# STM32MP25_CM33 register map
File version: 1.3
CPU: CM33 r0p1, little endian, MPU, FPU, vendor SysTick, 8 interrupt priority bits
Registers are 32-bit, read-write, reset 0x0 unless marked. A register's access mark holds for its fields unless they carry their own. Offsets are from the block's base; [hi:lo] are bit positions; lines under a group give offsets from that group; {n}, {i} and the like mark numbered series; 'fields as' and 'values as' point back to an identical list.

## ETHSW (part 1 of 2) — ETHSW register block
Base 0x4C000000
Same registers: ETHSW_S 0x5C000000
0x00 ETHSW_AC_DEV_IDR ro reset 0xD000 — ETHSW AC device ID register
  [23:8] DEVICE_ID
    208=AC
0x04 ETHSW_AC_INT_IDR ro reset 0x17E4078 — ETHSW AC int ID register
  [31:0] INT_ID — IP core version
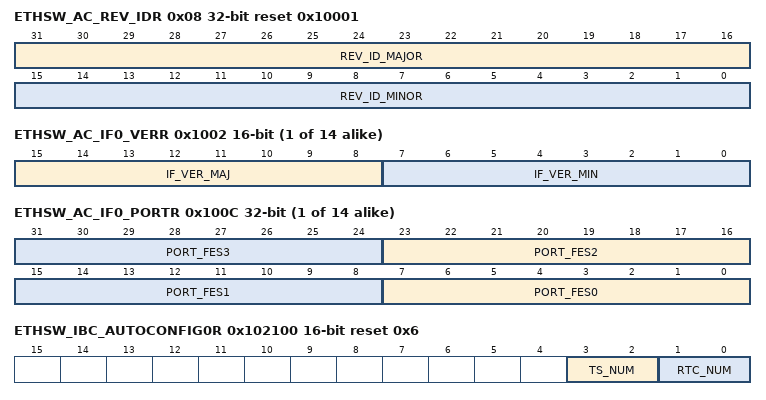
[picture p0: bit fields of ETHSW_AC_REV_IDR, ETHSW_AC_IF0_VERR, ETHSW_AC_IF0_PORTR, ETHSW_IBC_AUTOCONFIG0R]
0x08 ETHSW_AC_REV_IDR ro reset 0x10001 — ETHSW AC revision ID register
  [31:16] REV_ID_MAJOR — Revision ID major number
  [15:0] REV_ID_MINOR — Revision ID minor number
{0x1000+0x10*i} ETHSW_AC_IF{i}_IDR 16-bit ro (i=0..13) — ETHSW AC interface {i} ID register
  [15:0] INTERFACE_ID — Interface identification
    0=End of table; 1=Interface Map (this map); 16=Switch Management (of FES); 17=Switch Parameters (of FES); 18=Port Control Array (of FES); 19=Port Status Array (of FES); 20=Preemption (of FES); 21=Shapers (of FES); 22=Cut-Through (of FES); 23=HSR/PRP (of FES); 24=MACsec (of FES); 25=Port Timestamper (of FES); 26=Stream Identification (of FES); 27=Frame Replication and Elimination for Reliability (of FES); 28=Per-Stream Filtering and Policing (of FES); 32=Scheduled Traffic; 48=Clock; 64=Ethernet Interface Adapters
{0x1002+0x10*i} ETHSW_AC_IF{i}_VERR 16-bit ro (i=0..13) — ETHSW AC interface {i} version register
  [15:8] IF_VER_MAJ — Interface major number
  [7:0] IF_VER_MIN — Interface minor number
{0x1004+0x10*i} ETHSW_AC_IF{i}_BASER ro (i=0..13) — ETHSW AC interface {i} base address register
  [31:0] BASE — Base address
{0x1008+0x10*i} ETHSW_AC_IF{i}_LENR ro (i=0..13) — ETHSW AC interface {i} length register
  [31:0] LEN — Interface length
{0x100C+0x10*i} ETHSW_AC_IF{i}_PORTR ro (i=0..13) — ETHSW AC interface {i} port mapping register
  [all] fields
    0=not mapped to corresponding port of FES; 1=mapped to corresponding port of FES
  [8n+7:8n] PORT_FES{n} (n=0..3) — Port mapping to FES_{n}
0x10E0 ETHSW_AC_EOTR 16-bit ro — ETHSW AC end of table register
  [15:0] END_OF_TABLE — Static value 0x0 indicating end of table.
0x100000 ETHSW_IBC_DEV_IDR ro reset 0xE000 — ETHSW IBC device ID register
  [23:8] DEVICE_ID
    224=IBC
0x100004 ETHSW_IBC_INT_IDR ro reset 0x16A9932 — ETHSW IBC IP core ID register
  [31:0] INT_ID — IP core version
0x101000 ETHSW_IBC_GP_MUX_CTRLR 16-bit — ETHSW IBC general-purpose multiplexer control register
  [0] GPMUX0 — General-purpose (GP) multiplexer 0 control
    0=gp_in_a(0) connected to gp_out(0); 1=gp_in_b(0) connected to gp_out(0)
0x101100 ETHSW_IBC_TIME_MUX_CTRLR 16-bit — ETHSW IBC time interface mux demux control register
  [0] TIM_MUX0 — Time interface (TI) mux/demux 0 control
    0=time_in_a(0) connected to time_out(0), time_req_in(0) connected to time_req_out_a(0); 1=time_in_b(0) connected to time_out(0), time_req_in(0) connected to time_req_out_b(0)
0x102000 ETHSW_IBC_GP_MUXESR 16-bit ro reset 0x1 — ETHSW IBC generic GP_MUXES register
  [1:0] GPMUXES — The value of generic GP_MUXES
0x102002 ETHSW_IBC_GP_MUX_DEFAULTR 16-bit ro — ETHSW IBC generic GP_MUX_DEFAULT register
  [1:0] GPMUXDEF — The value of Generic GP_MUX_DEFAULT
0x102004 ETHSW_IBC_TIME_MUXESR 16-bit ro reset 0x1 — ETHSW IBC generic TIME_MUXES register
  [1:0] TIME_MUX — The value of Generic TIME_MUXES
0x102006 ETHSW_IBC_TIME_MUX_DEFAULTR 16-bit ro — ETHSW IBC generic TIME_MUX_DEFAULT register
  [1:0] TIM_MUXDEF — The value of Generic TIME_MUX_DEFAULT
0x102100 ETHSW_IBC_AUTOCONFIG0R 16-bit ro reset 0x6 — ETHSW IBC generic AUTOCONFIG0 register
  [3:2] TS_NUM — Number of Timestamper blocks (for example FPTS) in the system
  [1:0] RTC_NUM — Number of Real-Time Clock blocks (for example FRTC) in the system
0x102110 ETHSW_IBC_AUTOCONFIG8R 16-bit ro reset 0x8 — ETHSW IBC generic AUTOCONFIG8 register
  [15:0] RTC_ADD — Bits (31:16) of the base address of the first Real-Time Clock block
0x102112 ETHSW_IBC_AUTOCONFIG9R 16-bit ro reset 0x9 — ETHSW IBC generic AUTOCONFIG9 register
  [15:0] RTC_ADD — Bits (31:16) of the base address of the second real-time clock block
0x102114 ETHSW_IBC_AUTOCONFIG10R 16-bit ro — ETHSW IBC generic AUTOCONFIG10 register
  [15:0] RTC_ADD — Bits (31:16) of the base address of the third real-time clock block
0x102118 ETHSW_IBC_AUTOCONFIG12R 16-bit ro reset 0x2 — ETHSW IBC generic AUTOCONFIG12 register
  [15:0] TS_ADD — Bits (31:16) of the base address of the first timestamper (TS) block
0x10211A ETHSW_IBC_AUTOCONFIG13R 16-bit ro — ETHSW IBC generic AUTOCONFIG13 register
  [15:0] TS_ADD — Bits (31:16) of the base address of the second timestamper (TS) block
0x10211C ETHSW_IBC_AUTOCONFIG14R 16-bit ro — ETHSW IBC generic AUTOCONFIG14 register
  [15:0] TS_ADD — Bits (31:16) of the base address of the third timestamper (TS) block
0x120000 ETHSW_FTPS_GL0R ro reset 0x9100 — ETHSW FTPS general register 0
  [23:8] DEVICE_ID
    145=FTPS
0x120004 ETHSW_FTPS_GL1R ro — ETHSW FTPS general register 1
  [31:0] REV_ID — Revision ID
0x121000 ETHSW_FTPS_TSCR — ETHSW FTPS timestamper control register
  [0] GET_TIMESTAMP
0x121008 ETHSW_FTPS_TSIMR — ETHSW FTPS timestamper interrupt mask register
  [0] TIMESTAMP_IE — Timestamp interrupt enable
0x121010 ETHSW_FTPS_TSISR — ETHSW FTPS timestamper interrupt status register
  [0] TIMESTAMP_IS — Timestamp interrupt status
0x121100 ETHSW_FTPS_TS_SNSR ro — ETHSW FTPS timestamp subnanosecond register
  [31:0] SUBNANOSECONDS — Subnanoseconds part of the time of the PPx event
0x121104 ETHSW_FTPS_TS_NSR ro — ETHSW FTPS timestamp nanosecond register
  [29:0] NANOSECONDS — Nanoseconds part of the time of the PPx event
0x121108 ETHSW_FTPS_TS_SLR ro — ETHSW FTPS timestamp second low register
  [31:0] SECONDS — Least significant seconds part of the time of the PPx event
0x12110C ETHSW_FTPS_TS_SHR ro — ETHSW FTPS timestamp second high register
  [15:0] SECONDS — Most significant seconds part of the time of the PPx event
0x121110 ETHSW_FTPS_PCNTR ro — ETHSW FTPS pulse counter register
  [31:0] PCNT — Pulse counter
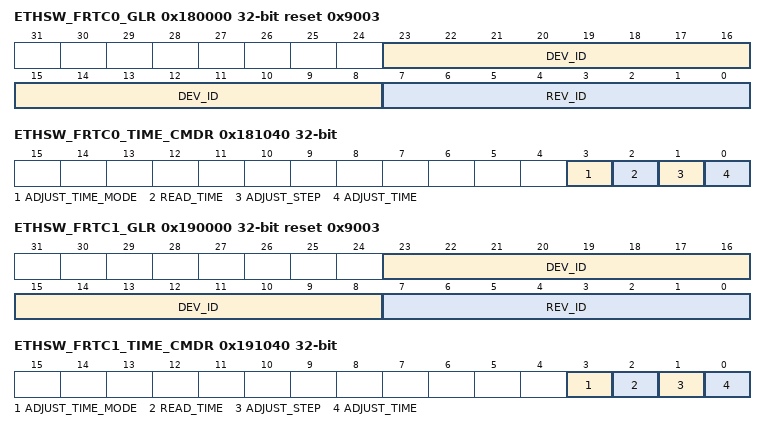
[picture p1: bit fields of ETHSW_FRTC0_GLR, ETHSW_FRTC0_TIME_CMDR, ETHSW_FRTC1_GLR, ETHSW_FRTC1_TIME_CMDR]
0x180000 ETHSW_FRTC0_GLR ro reset 0x9003 — ETHSW FRTC0 general register
  [23:8] DEV_ID — Device ID
    144=FRTC
  [7:0] REV_ID — Revision ID
0x181004 ETHSW_FRTC0_CUR_NSECR ro — ETHSW FRTC0 current time nanosecond register
  [29:0] NANOSECONDS — Nanoseconds part of the current time
0x181008 ETHSW_FRTC0_CUR_SECLR ro — ETHSW FRTC0 current time second low register
  [31:0] SECONDS — Seconds part of the current time (least significant part)
0x18100C ETHSW_FRTC0_CUR_SECHR ro — ETHSW FRTC0 current time second high register
  [15:0] SECONDS — Seconds part of the current time (most significant part)
0x181010 ETHSW_FRTC0_TIME_CCLR ro — ETHSW FRTC0 time CC low register
  [31:0] TIME_CC — Clock cycle counter (least significant part)
0x181014 ETHSW_FRTC0_TIME_CCHR ro — ETHSW FRTC0 time CC high register
  [15:0] TIME_CC — Clock cycle counter (most significant part)
0x181020 ETHSW_FRTC0_STEP_SIZE_SNR — ETHSW FRTC0 step size subnanosecond register
  [31:0] SUBNANOSECONDS
0x181024 ETHSW_FRTC0_STEP_SIZE_NR reset 0x5 — ETHSW FRTC0 step size nanosecond register
  [5:0] NANOSECONDS
0x181034 ETHSW_FRTC0_ADJUST_NSECR — ETHSW FRTC0 adjust nanosecond register
  [29:0] NANOSECONDS
0x181038 ETHSW_FRTC0_ADJUST_SECLR — ETHSW FRTC0 adjust second low register
  [31:0] SECONDS — Seconds (least significant part)
0x18103C ETHSW_FRTC0_ADJUST_SECHR — ETHSW FRTC0 adjust second high register
  [15:0] SECONDS — Seconds (most significant part)
0x181040 ETHSW_FRTC0_TIME_CMDR — ETHSW FRTC0 time command register
  [3] ADJUST_TIME_MODE — Determines when ADJUST_TIME command is taken into use (does not affect to ADJUST_STEP command):
    0=takes effect immediately (normal behavior); 1=takes effect on half second (2less thansup>29less than/sup> = ~536,9ms on nanoseconds value)
  [2] READ_TIME — Updates the following registers with the current values in the NCO:
  [1] ADJUST_STEP — Take the new values of the following registers into use:
  [0] ADJUST_TIME — Adds (for one time only) the values in the following registers to internal time (NCO):
0x182000 ETHSW_FRTC0_GENERICS_LR ro — ETHSW FRTC0 generics low register
  [31:0] DEFAULT_STEP_SNS — The value of Generic DEFAULT_STEP_SNS.
0x182004 ETHSW_FRTC0_GENERICS_HR ro reset 0x5 — ETHSW FRTC0 generics high register
  [5:0] DEFAULT_STEP_NS — The value of Generic DEFAULT_STEP_NS.
0x190000 ETHSW_FRTC1_GLR ro reset 0x9003 — ETHSW FRTC1 general register
  [23:8] DEV_ID — Device ID
    144=FRTC
  [7:0] REV_ID — Revision ID
0x191004 ETHSW_FRTC1_CUR_NSECR ro — ETHSW FRTC1 current time nanosecond register
  [29:0] NANOSECONDS — Nanoseconds part of the current time
0x191008 ETHSW_FRTC1_CUR_SECLR ro — ETHSW FRTC1 current time second low register
  fields as ETHSW_FRTC0_CUR_SECLR
0x19100C ETHSW_FRTC1_CUR_SECHR ro — ETHSW FRTC1 current time second high register
  fields as ETHSW_FRTC0_CUR_SECHR
0x191010 ETHSW_FRTC1_TIME_CCLR ro — ETHSW FRTC1 time CC low register
  [31:0] TIME_CC — Clock cycle counter (least significant part)
0x191014 ETHSW_FRTC1_TIME_CCHR ro — ETHSW FRTC1 time CC high register
  [15:0] TIME_CC — Clock cycle counter (most significant part)
0x191020 ETHSW_FRTC1_STEP_SIZE_SNR — ETHSW FRTC1 step size subnanosecond register
  [31:0] SUBNANOSECONDS
0x191024 ETHSW_FRTC1_STEP_SIZE_NR reset 0x5 — ETHSW FRTC1 step size nanosecond register
  [5:0] NANOSECONDS
0x191034 ETHSW_FRTC1_ADJUST_NSECR — ETHSW FRTC1 adjust nanosecond register
  [29:0] NANOSECONDS
0x191038 ETHSW_FRTC1_ADJUST_SECLR — ETHSW FRTC1 adjust second low register
  [31:0] SECONDS — Seconds (least significant part)
0x19103C ETHSW_FRTC1_ADJUST_SECHR — ETHSW FRTC1 adjust second high register
  [15:0] SECONDS — Seconds (most significant part)
0x191040 ETHSW_FRTC1_TIME_CMDR — ETHSW FRTC1 time command register
  fields as ETHSW_FRTC0_TIME_CMDR
0x192000 ETHSW_FRTC1_GENERICS_LR ro — ETHSW FRTC1 generics low register
  [31:0] DEFAULT_STEP_SNS — The value of Generic DEFAULT_STEP_SNS.
0x192004 ETHSW_FRTC1_GENERICS_HR ro reset 0x5 — ETHSW FRTC1 generics high register
  [5:0] DEFAULT_STEP_NS — The value of Generic DEFAULT_STEP_NS.
0x1C0000 ETHSW_FSC_DEV_IDR ro reset 0xC000 — ETHSW FSC device ID register
  [23:8] DEV_ID — Device ID
    192=FSC
0x1C0004 ETHSW_FSC_INT_IDR ro reset 0x16A9932 — ETHSW FSC INT ID register
  [31:0] REV_ID
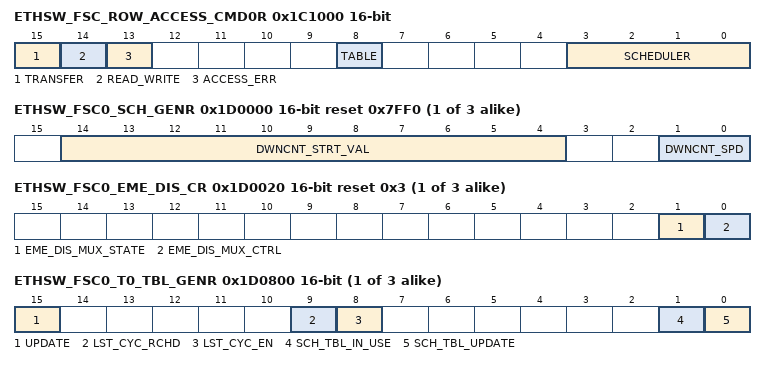
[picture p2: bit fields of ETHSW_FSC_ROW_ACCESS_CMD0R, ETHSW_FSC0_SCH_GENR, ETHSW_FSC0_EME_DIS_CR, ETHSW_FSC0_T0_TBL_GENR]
0x1C1000 ETHSW_FSC_ROW_ACCESS_CMD0R 16-bit — ETHSW FSC schedule table row access command register 0
  [15] TRANSFER — Triggers transfer between schedule table row and ROW_DATA registers
  [14] READ_WRITE
    0=Read; 1=Write
  [13] ACCESS_ERR ro — Access error.
    0=The previous read/write was successful; 1=The previous write access was not successful because the table was in use by the scheduler (=active)
  [8] TABLE — Schedule table.
    0=Table 0; 1=Table 1
  [3:0] SCHEDULER
    0=Scheduler 0; 1=Scheduler 1
0x1C1002 ETHSW_FSC_ROW_ACCESS_CMD1R 16-bit ro — ETHSW FSC schedule table row access command register 1
  [9:0] ROW_NUM — Row number
0x1C1010 ETHSW_FSC_ROW_DATA0R 16-bit — ETHSW FSC schedule table row data 0 register
  [8:0] OUTPUT_STATE — Output state for outputs 8 to 0.
    0=Gate state is Closed; 1=Gate state is Open
0x1C1018 ETHSW_FSC_ROW_DATA4R 16-bit — ETHSW FSC schedule table row data 4 register
  [15:0] TIME — Time in clock cycles
0x1C1100 ETHSW_FSC_IMR 16-bit — ETHSW FSC interrupt mask register
  [0] SCHTBL_IE — Schedule table interrupt enable
0x1C1102 ETHSW_FSC_ISR 16-bit — ETHSW FSC interrupt status register
  [0] SCHTBL_IS — Schedule table interrupt status
0x1C4000 ETHSW_FSC_GEN_SCHR 16-bit ro reset 0x7 — ETHSW FSC generic scheduler register
  [15:0] SCHEDULERS — The value of generic SCHEDULERS
0x1C4002 ETHSW_FSC_GEN_OUTR 16-bit ro reset 0x9 — ETHSW FSC generic outputs register
  [6:0] OUTPUTS — The value of generic OUTPUTS
    1=1 output
0x1C4004 ETHSW_FSC_GEN_TBL_RWR 16-bit ro reset 0xA — ETHSW FSC generic table rows register
  [3:0] TABLE_ROWS — The value of generic TABLE_ROWS
0x1C4006 ETHSW_FSC_GEN_CLK_FRQR 16-bit ro reset 0xC8 — ETHSW FSC generic clock frequency register
  [7:0] CLK_FREQ — The value of generic CLK_FREQ
    1=1MHz
{0x1D0000+0x1000*i} ETHSW_FSC{i}_SCH_GENR 16-bit reset 0x7FF0 (i=0..2) — ETHSW FSC scheduler {i} general register
  [14:4] DWNCNT_STRT_VAL — Downcounter start value.
  [1:0] DWNCNT_SPD — Downcounter speed, 10/100 divider
    0=one addend in a clock cycle (see ETHSW FSC scheduler x downcounter speed setting register (ETHSW_FSCx_DWNCNT_SPDR) (x = 0 to 2)); 1=one addend in ten clock cycles; 2=one addend in one hundred clock cycles
{0x1D0002+0x1000*i} ETHSW_FSC{i}_DWNCNT_SPDR 16-bit reset 0x100 (i=0..2) — ETHSW FSC scheduler {i} downcounter speed setting register
  [8:5] DWNCNTR_SPD — Downcounter speed, addend
    5=0; 8=one unit in a clock cycle; 10=1
{0x1D0020+0x1000*i} ETHSW_FSC{i}_EME_DIS_CR 16-bit reset 0x3 (i=0..2) — ETHSW FSC scheduler {i} emergency disable control register
  [1] EME_DIS_MUX_STATE ro — Current state of emergency disable MUX
    0=signals to downcounters / gate_state outputs are from scheduler; 1=signals to downcounters / gate state outputs are from ETHSW FSC scheduler x emergency disable port state register (ETHSW_FSCx_EME_DIS_STATR) (x = 0 to 2)
  [0] EME_DIS_MUX_CTRL — Emergency disable MUX control
    0=set MUX so that signals to downcounters/gate_state outputs are from scheduler; 1=set MUX so that signals to downcounters/gate state outputs are from ETHSW FSC scheduler x emergency disable port state register (ETHSW_FSCx_EME_DIS_STATR) (x = 0 to 2)
{0x1D0030+0x1000*i} ETHSW_FSC{i}_EME_DIS_STATR 16-bit reset 0xFF (i=0..2) — ETHSW FSC scheduler {i} emergency disable port state register
  [8:0] EME_DIS_STAT — Gate state in Emergency disable mode
    0=gate_state is closed; 1=gate_state is open
{0x1D0800+0x1000*i} ETHSW_FSC{i}_T0_TBL_GENR 16-bit (i=0..2) — ETHSW FSC scheduler {i} table 0 general control and status register
  [15] UPDATE
  [9] LST_CYC_RCHD ro — Last cycle reached
    0=Disabled, cycler process goes on forever; 1=Enabled, cycler process stops when last cycle is reached
  [8] LST_CYC_EN — Last cycle number register enable/disable
    values as LST_CYC_RCHD
  [1] SCH_TBL_IN_USE ro — Schedule table currently in use
    0=This table is not currently in use; 1=This table is in use
  [0] SCH_TBL_UPDATE — Schedule table can be taken into use
    0=cannot be taken into use; 1=can be taken into use
{0x1D0814+0x1000*i} ETHSW_FSC{i}_T0_STRT_NSR (i=0..2) — ETHSW FSC scheduler {i} table 0 start time nanosecond register
  [29:0] STARTTIME_NS — Time schedule table taken into use, nanoseconds part.
{0x1D0818+0x1000*i} ETHSW_FSC{i}_T0_STRT_SR 16-bit (i=0..2) — ETHSW FSC scheduler {i} table 0 start time second register
  [7:0] STARTTIME_S — Time schedule table taken into use, seconds part.
{0x1D0820+0x1000*i} ETHSW_FSC{i}_T0_CYC_SUBNSR (i=0..2) — ETHSW FSC scheduler {i} table 0 cycle time subnanosecond register
  [31:8] CYCLETIME_SUBNS — Time each cycle is run, subnanoseconds part.
{0x1D0824+0x1000*i} ETHSW_FSC{i}_T0_CYC_NSR (i=0..2) — ETHSW FSC scheduler {i} table 0 cycle time nanosecond register
  [29:0] CYCLETIME_NS — Time each cycle is run, nanoseconds part.
{0x1D0834+0x1000*i} ETHSW_FSC{i}_T0_CYCTS_NSR ro (i=0..2) — ETHSW FSC scheduler {i} table 0 cycle timestamp nanosecond register
  [29:0] TIMESTAMP_NS — Timestamp from the start of the previous cycle, nanoseconds part.
{0x1D0838+0x1000*i} ETHSW_FSC{i}_T0_CYCTS_SR ro (i=0..2) — ETHSW FSC scheduler {i} table 0 cycle timestamp second register
  [7:0] TIMESTAMP_S — Timestamp from the start of the previous cycle, seconds part.
{0x1D0840+0x1000*i} ETHSW_FSC{i}_T0_CYC_CNTR 16-bit ro (i=0..2) — ETHSW FSC scheduler {i} table 0 cycle counter register
  [15:0] CYCLE_CNT — Cycle count.
{0x1D0844+0x1000*i} ETHSW_FSC{i}_T0_LST_CYCR 16-bit ro (i=0..2) — ETHSW FSC scheduler {i} table 0 last cycle register
  [15:0] LAST_CYCLE — Cycle number of the last cycle.
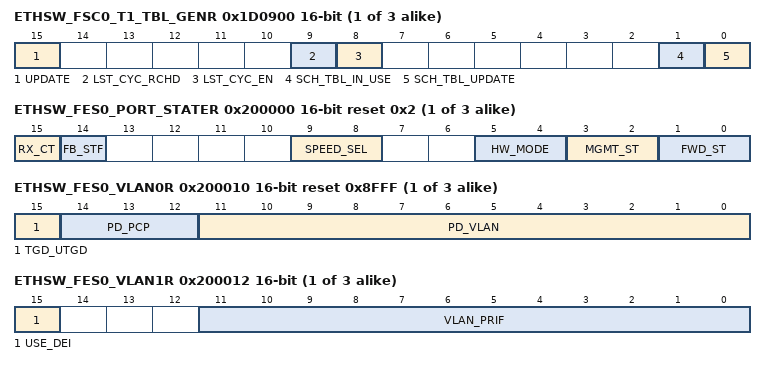
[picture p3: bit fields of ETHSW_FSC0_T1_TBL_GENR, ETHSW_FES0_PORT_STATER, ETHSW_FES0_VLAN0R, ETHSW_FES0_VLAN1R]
{0x1D0900+0x1000*i} ETHSW_FSC{i}_T1_TBL_GENR 16-bit (i=0..2) — ETHSW FSC scheduler {i} table 1 general control and status register
  fields as ETHSW_FSC0_T0_TBL_GENR
{0x1D0914+0x1000*i} ETHSW_FSC{i}_T1_STRT_NSR (i=0..2) — ETHSW FSC scheduler {i} table 1 start time nanosecond register
  fields as ETHSW_FSC0_T0_STRT_NSR
{0x1D0918+0x1000*i} ETHSW_FSC{i}_T1_STRT_SR 16-bit (i=0..2) — ETHSW FSC scheduler {i} table 1 start time second register
  fields as ETHSW_FSC0_T0_STRT_SR
{0x1D0920+0x1000*i} ETHSW_FSC{i}_T1_CYC_SUBNSR (i=0..2) — ETHSW FSC scheduler {i} table 1 cycle time subnanosecond register
  fields as ETHSW_FSC0_T0_CYC_SUBNSR
{0x1D0924+0x1000*i} ETHSW_FSC{i}_T1_CYC_NSR (i=0..2) — ETHSW FSC scheduler {i} table 1 cycle time nanosecond register
  [29:0] CYCLETIME_NS — Time each cycle is run, nanoseconds part.
{0x1D0934+0x1000*i} ETHSW_FSC{i}_T1_CYCTS_NSR ro (i=0..2) — ETHSW FSC scheduler {i} table 1 cycle timestamp nanosecond register
  fields as ETHSW_FSC0_T0_CYCTS_NSR
{0x1D0938+0x1000*i} ETHSW_FSC{i}_T1_CYCTS_SR ro (i=0..2) — ETHSW FSC scheduler {i} table 1 cycle timestamp second register
  fields as ETHSW_FSC0_T0_CYCTS_SR
{0x1D0940+0x1000*i} ETHSW_FSC{i}_T1_CYC_CNTR 16-bit ro (i=0..2) — ETHSW FSC scheduler {i} table 1 cycle counter register
  [15:0] CYCLE_CNT — Cycle count.
{0x1D0944+0x1000*i} ETHSW_FSC{i}_T1_LST_CYCR 16-bit ro (i=0..2) — ETHSW FSC scheduler {i} table 1 last cycle register
  [15:0] LAST_CYCLE — Cycle number of the last cycle.
{0x200000+0x10000*i} ETHSW_FES{i}_PORT_STATER 16-bit reset 0x2 (i=0..2) — ETHSW FES port {i} port State register
  [15] RX_CT — RX Cut-through
    0=Cut-through disabled for frames coming into this port; 1=Cut-through enabled for frames coming into this port
  [14] FB_STF — Fallback to Store-and-Forward
    0=RX Cut-through bit (RX_CT) is cleared with a probability of 1/256 in case of a receive error; 1=RX Cut-through bit (RX_CT) is never automatically cleared
  [9:8] SPEED_SEL — Speed select
    1=1000Mb/s; 2=100Mb/s; 3=10Mb/s
  [5:4] HW_MODE — Port HW mode
    0=MII; 2=GMII
  [3:2] MGMT_ST — Port management state
    0=Normal mode; 1=Management mode
  [1:0] FWD_ST — Port Forwarding state
    0=Forwarding; 2=Disabled
{0x200010+0x10000*i} ETHSW_FES{i}_VLAN0R 16-bit reset 0x8FFF (i=0..2) — ETHSW FES port {i} port VLAN configuration register 0
  [15] TGD_UTGD — Tagged/untagged
    0=no VLAN tags is added to the frames at exit; 1=VLAN tags are added to frames at exit, except for frames whose VLAN is the default VLAN of the output port
  [14:12] PD_PCP — Port default PCP
  [11:0] PD_VLAN — Port default VLAN
{0x200012+0x10000*i} ETHSW_FES{i}_VLAN1R 16-bit (i=0..2) — ETHSW FES port {i} port VLAN configuration register 1
  [15] USE_DEI
    0=DEI bit is not used for this port; 1=DEI bit is used for this port
  [11:0] VLAN_PRIF — Default VLAN for Priority Tagged Frames
{0x200014+0x10000*i} ETHSW_FES{i}_FWDM_CFGR 16-bit (i=0..2) — ETHSW FES port {i} port forward mask configuration register
  [2:0] PORT_FWDM — Port forward mask
    0=Enable forwarding to the port; 1=Disable forwarding to the port
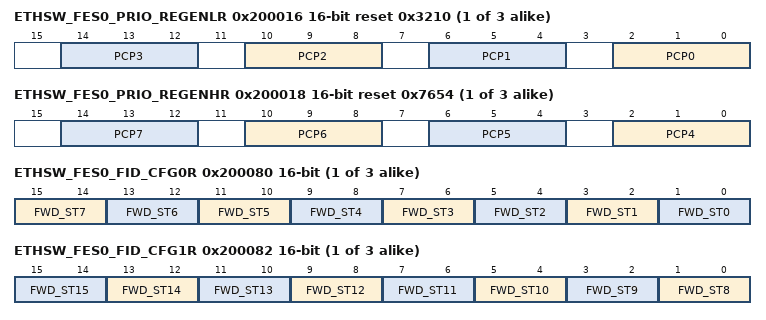
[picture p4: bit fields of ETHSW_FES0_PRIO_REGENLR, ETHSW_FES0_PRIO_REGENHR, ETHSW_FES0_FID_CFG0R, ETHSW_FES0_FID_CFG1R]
{0x200016+0x10000*i} ETHSW_FES{i}_PRIO_REGENLR 16-bit reset 0x3210 (i=0..2) — ETHSW FES port {i} priority regeneration table low register
  [4n+2:4n] PCP{n} (n=0..3) — Priority, PCP{n}
{0x200018+0x10000*i} ETHSW_FES{i}_PRIO_REGENHR 16-bit reset 0x7654 (i=0..2) — ETHSW FES port {i} priority regeneration table high register
  [4n-14:4n-16] PCP{n} (n=4..7) — Priority, PCP{n}
{0x200030+2i} ETHSW_FES0_SHAPER{i}R 16-bit reset 0xFFFF (i=0..7) — ETHSW FES port 0 shaper {i} configuration register
  [15:0] ADDEND
{0x200040+2i} ETHSW_FES0_FRAMESIZE{i}R 16-bit reset 0x7FF (i=0..7) — ETHSW FES port 0 frame size {i} configuration register
  [10:0] FRAMESIZE — Max frame size
{0x200080+0x10000*i} ETHSW_FES{i}_FID_CFG0R 16-bit (i=0..2) — ETHSW FES port {i} filtering identifier configuration register 0
  [2n+1:2n] FWD_ST{n} (n=1..7) — Port Forwarding state for FID {n}
  [1:0] FWD_ST0 — Port Forwarding state for FID 0
    0=Forwarding; 1=Learning; 2=Disabled
{0x200082+0x10000*i} ETHSW_FES{i}_FID_CFG1R 16-bit (i=0..2) — ETHSW FES port {i} filtering identifier configuration register 1
  [2n-15:2n-16] FWD_ST{n} (n=8..15) — Port Forwarding state for FID {n}
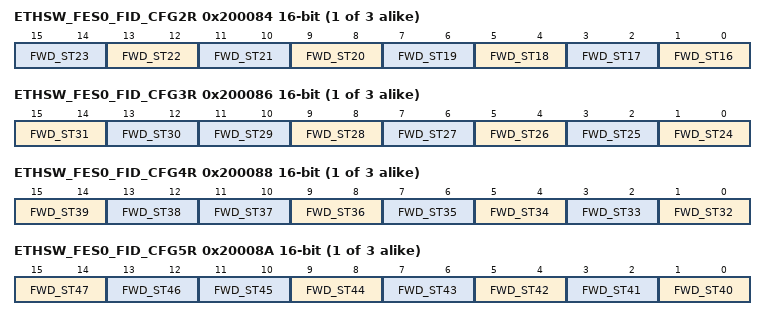
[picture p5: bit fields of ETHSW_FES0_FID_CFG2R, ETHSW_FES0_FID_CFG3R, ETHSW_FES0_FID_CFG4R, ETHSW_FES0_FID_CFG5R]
{0x200084+0x10000*i} ETHSW_FES{i}_FID_CFG2R 16-bit (i=0..2) — ETHSW FES port {i} filtering identifier configuration register 2
  [2n-31:2n-32] FWD_ST{n} (n=16..23) — Port Forwarding state for FID {n}
{0x200086+0x10000*i} ETHSW_FES{i}_FID_CFG3R 16-bit (i=0..2) — ETHSW FES port {i} filtering identifier configuration register 3
  [15:14] FWD_ST31 — Port Forwarding state for FID 31
  [13:12] FWD_ST30 — Port Forwarding state for FID30
  [2n-47:2n-48] FWD_ST{n} (n=24..29) — Port Forwarding state for FID {n}
{0x200088+0x10000*i} ETHSW_FES{i}_FID_CFG4R 16-bit (i=0..2) — ETHSW FES port {i} filtering identifier configuration register 4
  [15:14] FWD_ST39 — Port Forwarding state for FID 39
  [13:12] FWD_ST38 — Port Forwarding state for FID38
  [2n-63:2n-64] FWD_ST{n} (n=32..37) — Port Forwarding state for FID {n}
{0x20008A+0x10000*i} ETHSW_FES{i}_FID_CFG5R 16-bit (i=0..2) — ETHSW FES port {i} filtering identifier configuration register 5
  [15:14] FWD_ST47 — Port Forwarding state for FID 47
  [13:12] FWD_ST46 — Port Forwarding state for FID46
  [2n-79:2n-80] FWD_ST{n} (n=40..45) — Port Forwarding state for FID {n}
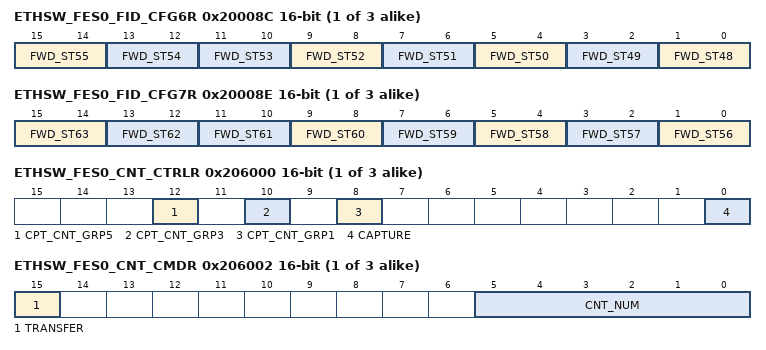
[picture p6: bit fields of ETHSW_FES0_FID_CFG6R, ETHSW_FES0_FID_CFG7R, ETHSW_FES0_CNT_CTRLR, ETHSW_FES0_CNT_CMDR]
{0x20008C+0x10000*i} ETHSW_FES{i}_FID_CFG6R 16-bit (i=0..2) — ETHSW FES port {i} filtering identifier configuration register 6
  [15:14] FWD_ST55 — Port Forwarding state for FID 55
  [13:12] FWD_ST54 — Port Forwarding state for FID54
  [2n-95:2n-96] FWD_ST{n} (n=48..53) — Port Forwarding state for FID {n}
{0x20008E+0x10000*i} ETHSW_FES{i}_FID_CFG7R 16-bit (i=0..2) — ETHSW FES port {i} filtering identifier configuration register 7
  [15:14] FWD_ST63 — Port Forwarding state for FID 63
  [13:12] FWD_ST62 — Port Forwarding state for FID62
  [2n-111:2n-112] FWD_ST{n} (n=56..61) — Port Forwarding state for FID {n}
{0x2000C0+0x10000*i} ETHSW_FES{i}_FL_CAPTR 16-bit (i=0..2) — ETHSW FES port {i} buffer fill level capture register
  [0] CAPTURE
{0x2000C2+0x10000*i} ETHSW_FES{i}_FL_SMPL_CNTR 16-bit (i=0..2) — ETHSW FES port {i} buffer fill level sample counter register
  [15:0] FL_SAMPLE_CNT — Sample counter
{0x2000E0+2i} ETHSW_FES0_FL_Q{i}_MINR 16-bit (i=0..7) — ETHSW FES port 0 minimum fill level queue {i} register
  [4:0] FL_QY_MIN — Minimum fill level for queue y
{0x2000F0+2i} ETHSW_FES0_FL_Q{i}_MAXR 16-bit (i=0..7) — ETHSW FES port 0 maximum fill level queue {i} register
  [4:0] FL_QY_MAX — Maximum fill level for queue y
{0x204000+0x10000*i} ETHSW_FES{i}_PTP_RX_SYNCD_SNSR 16-bit (i=0..2) — ETHSW FES PTP RX sync delay subnanosecond register
  [15:0] PTP_RX_SYNC_DELAY_SUBNS — RX Sync delay, subnanoseconds
{0x204002+0x10000*i} ETHSW_FES{i}_PTP_RX_SYNCD_NSLR 16-bit (i=0..2) — ETHSW FES PTP RX sync delay nanosecond low register
  [15:0] PTP_RX_SYNC_DELAY_NSL — RX Sync delay, nanoseconds low part
{0x204004+0x10000*i} ETHSW_FES{i}_PTP_RX_SYNCD_NSHR 16-bit (i=0..2) — ETHSW FES PTP RX sync delay nanosecond high register
  [7:0] PTP_RX_SYNC_DELAY_NSH — RX Sync delay, nanoseconds high part
{0x204008+0x10000*i} ETHSW_FES{i}_PTP_RX_EVENTD_SNSR 16-bit (i=0..2) — ETHSW FES PTP RX event delay subnanosecond register
  [15:0] PTP_RX_EVENT_DELAY_SNS — RX Event delay, subnanoseconds
{0x20400A+0x10000*i} ETHSW_FES{i}_PTP_RX_EVENTD_NSR 16-bit (i=0..2) — ETHSW FES PTP RX event delay nanosecond register
  [15:0] PTP_RX_EVENT_DELAY_NS — RX Event delay, nanoseconds
{0x204010+0x10000*i} ETHSW_FES{i}_PTP_TX_EVENTD_SNSR 16-bit (i=0..2) — ETHSW FES PTP TX event delay subnanosecond register
  [15:0] PTP_TX_EVENT_DELAY_SNS — TX Event delay, subnanoseconds
{0x204012+0x10000*i} ETHSW_FES{i}_PTP_TX_EVENTD_NSR 16-bit (i=0..2) — ETHSW FES PTP TX event delay nanosecond register
  [15:0] PTP_TX_EVENT_DELAY_NS — TX Event delay, nanoseconds
{0x206000+0x10000*i} ETHSW_FES{i}_CNT_CTRLR 16-bit (i=0..2) — ETHSW FES port {i} counter control register
  [12] CPT_CNT_GRP5 — Capture counter group 5
    0=Capture counter TX_OVERRUN; 1=Do not capture above mentioned counter
  [10] CPT_CNT_GRP3 — Capture counter group 3
    0=Capture counters RX_PREEMPT_SMD_ERR, RX_PREEMPT_ASS_ERR, RX_PREEMPT_ASS_OK, RX_PREEMPT_FRAG_CNT, TX_PREEMPT_FRAG_CNT; 1=Do not capture above mentioned counters
  [8] CPT_CNT_GRP1 — Capture counter group 1
    0=Capture counters RX_GOOD_OCTETS, RX_BAD_OCTETS,RX_UNICAST, RX_BROADCAST, RX_MULTICAST, RX_UNDERSIZE,RX_FRAGMENTS, RX_OVERSIZE, RX_JABBER, RX_ERR, RX_CRC,RX_64, RX_65_127, RX_128_255, RX_256_511, RX_512_1023,RX_1024_1536, FULL_DROP, RX_POLICED, TX_OCTETS, TX_UNICAST, TX _BROADCAST, TX _MULTICAST, Q_DROP, EARLY_DROP; 1=Do not capture above mentioned counters
  [0] CAPTURE
{0x206002+0x10000*i} ETHSW_FES{i}_CNT_CMDR 16-bit (i=0..2) — ETHSW FES port {i} counter command register
  [15] TRANSFER
  [5:0] CNT_NUM — Counter number
{0x206008+0x10000*i} ETHSW_FES{i}_CNT_VAL_LOR 16-bit (i=0..2) — ETHSW FES port {i} counter value low register
  [15:0] CNT_VAL_LO — Counter value Low
{0x20600A+0x10000*i} ETHSW_FES{i}_CNT_VAL_HIR 16-bit (i=0..2) — ETHSW FES port {i} counter value high register
  [15:0] CNT_VAL_HI — Counter value High
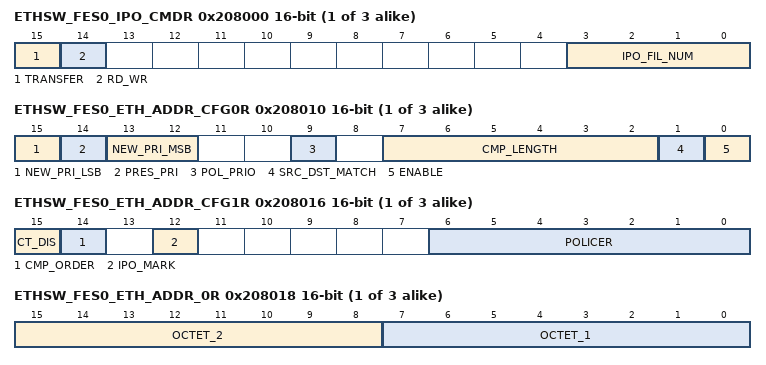
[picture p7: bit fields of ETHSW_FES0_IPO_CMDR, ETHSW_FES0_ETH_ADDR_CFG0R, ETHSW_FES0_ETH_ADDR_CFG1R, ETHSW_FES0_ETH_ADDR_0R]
{0x208000+0x10000*i} ETHSW_FES{i}_IPO_CMDR 16-bit (i=0..2) — ETHSW FES port {i} IPO command register
  [15] TRANSFER
  [14] RD_WR — Read/write
    0=Read from IPO filter to registers:; 1=Write from registers (see above) to IPO filter
  [3:0] IPO_FIL_NUM — IPO Filter Number
{0x208010+0x10000*i} ETHSW_FES{i}_ETH_ADDR_CFG0R 16-bit (i=0..2) — ETHSW FES port {i} IPO filter configuration register 0
  [15] NEW_PRI_LSB — New priority, LSB
  [14] PRES_PRI — Preserve priority
    0=Set the frame priority to the value in New priority bits; 1=Do not alter the frame priority
  [13:12] NEW_PRI_MSB — New priority, MSBs
  [9] POL_PRIO — Policer priority
    0=Normal Policer priority; 1=Low Policer priority, frames with lower policer priority use only the upper half of the token buckets
  [7:2] CMP_LENGTH — Compared Length
  [1] SRC_DST_MATCH — Source/Destination Match
    0=Match to destination address; 1=Match to source address
  [0] ENABLE
    0=Rule disabled; 1=Rule enabled
{0x208012+0x10000*i} ETHSW_FES{i}_ETH_ADDR_FWD_ALLOWR 16-bit (i=0..2) — ETHSW FES port {i} forward allow register
  [2:0] FWD_ALLOW_MSK — Forward allow mask
    0=Forwarding is not allowed to this port; 1=Forwarding is allowed to this port
{0x208014+0x10000*i} ETHSW_FES{i}_ETH_ADDR_FWD_MIRRORR 16-bit (i=0..2) — ETHSW FES port {i} forward mirror register
  [2:0] FWD_MIRROR_MSK — Forward mirror mask
    0=Frame is not mirrored to this port; 1=Frame is mirrored to this port
{0x208016+0x10000*i} ETHSW_FES{i}_ETH_ADDR_CFG1R 16-bit (i=0..2) — ETHSW FES port {i} IPO filter configuration register 1
  [15] CT_DIS — Cut-Through disable
    0=Cut-through is possible for the frame if all the other requirements for cut-through forwarding are met; 1=Cut-through is disabled for the matching frames
  [14] CMP_ORDER — Compare Order
    0=The order is the order in which bits come from the line, that is the highest byte first, but the lowest bit of the byte first; 1=The order is the highest byte first and the highest bit of the byte first
  [12] IPO_MARK
  [6:0] POLICER
{0x208018+0x10000*i} ETHSW_FES{i}_ETH_ADDR_0R 16-bit (i=0..2) — ETHSW FES port {i} ethernet address part 0 register
  [15:8] OCTET_2 — 2less thansup>ndless than/sup> octet
  [7:0] OCTET_1 — 1less thansup>stless than/sup> octet
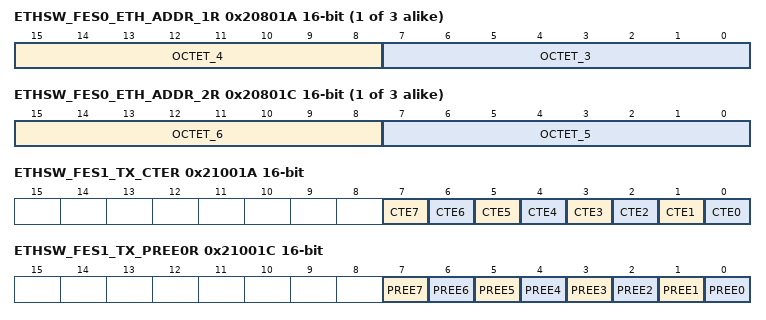
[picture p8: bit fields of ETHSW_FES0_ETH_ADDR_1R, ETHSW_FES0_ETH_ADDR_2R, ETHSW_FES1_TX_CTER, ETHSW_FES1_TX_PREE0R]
{0x20801A+0x10000*i} ETHSW_FES{i}_ETH_ADDR_1R 16-bit (i=0..2) — ETHSW FES port {i} ethernet address part 1 register
  [15:8] OCTET_4 — 4less thansup>thless than/sup> octet
  [7:0] OCTET_3 — 3less thansup>rdless than/sup> octet
{0x20801C+0x10000*i} ETHSW_FES{i}_ETH_ADDR_2R 16-bit (i=0..2) — ETHSW FES port {i} ethernet address part 2 register
  [15:8] OCTET_6 — 6less thansup>thless than/sup> octet
  [7:0] OCTET_5 — 5less thansup>thless than/sup> octet
0x21001A ETHSW_FES1_TX_CTER 16-bit — ETHSW FES port 1 TX cut-through enable register
  [n] CTE{n} (n=1..7) — Cut-through enable/disable for queue {n}
  [0] CTE0 — Cut-through enable/disable for queue 0
    0=Cut-through disabled; 1=Cut-through enabled
0x21001C ETHSW_FES1_TX_PREE0R 16-bit — ETHSW FES port 1 TX preemptable traffic selection register 0
  [n] PREE{n} (n=1..7) — Preemption setting for queue {n}
  [0] PREE0 — Preemption setting for queue 0
    0=Express; 1=Preemptable
0x21001E ETHSW_FES1_TX_PREE1R 16-bit — ETHSW FES port 1 TX preemptable traffic selection register 1
  [1:0] ADDFRAGSIZE
    0=60 octets; 1=124 octets; 2=188 octets; 3=252 octets
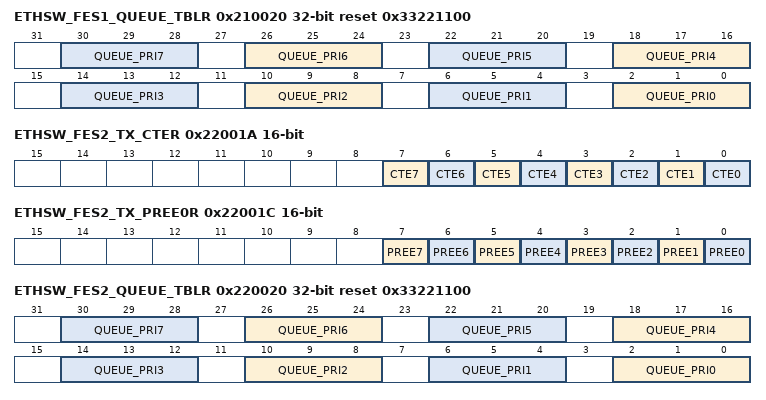
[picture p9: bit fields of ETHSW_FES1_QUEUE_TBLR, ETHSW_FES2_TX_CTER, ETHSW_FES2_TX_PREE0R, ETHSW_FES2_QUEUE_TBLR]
0x210020 ETHSW_FES1_QUEUE_TBLR reset 0x33221100 — ETHSW FES port 1 queue table configuration register
  [4n+2:4n] QUEUE_PRI{n} (n=0..7) — Queue for priority {n}
{0x210030+2i} ETHSW_FES1_SHAPER{i}R 16-bit reset 0xFFFF (i=0..7) — ETHSW FES port 1 shaper {i} configuration register
  [15:0] ADDEND
{0x210040+2i} ETHSW_FES1_FRAMESIZE{i}R 16-bit reset 0x7FF (i=0..7) — ETHSW FES port 1 frame size {i} configuration register
  [10:0] FRAMESIZE — Max frame size
{0x2100E0+2i} ETHSW_FES1_FL_Q{i}_MINR 16-bit (i=0..7) — ETHSW FES port 1 minimum fill level queue {i} register
  [4:0] FL_QY_MIN — Minimum fill level for queue y
{0x2100F0+2i} ETHSW_FES1_FL_Q{i}_MAXR 16-bit (i=0..7) — ETHSW FES port 1 maximum fill level queue {i} register
  [4:0] FL_QY_MAX — Maximum fill level for queue y
0x22001A ETHSW_FES2_TX_CTER 16-bit — ETHSW FES port 2 TX cut-through enable register
  fields as ETHSW_FES1_TX_CTER
0x22001C ETHSW_FES2_TX_PREE0R 16-bit — ETHSW FES port 2 TX preemptable traffic selection register 0
  fields as ETHSW_FES1_TX_PREE0R
0x22001E ETHSW_FES2_TX_PREE1R 16-bit — ETHSW FES port 2 TX preemptable traffic selection register 1
  fields as ETHSW_FES1_TX_PREE1R
0x220020 ETHSW_FES2_QUEUE_TBLR reset 0x33221100 — ETHSW FES port 2 queue table configuration register
  [4n+2:4n] QUEUE_PRI{n} (n=0..7) — Queue for priority {n}
{0x220030+2i} ETHSW_FES2_SHAPER{i}R 16-bit reset 0xFFFF (i=0..7) — ETHSW FES port 2 shaper {i} configuration register
  [15:0] ADDEND
